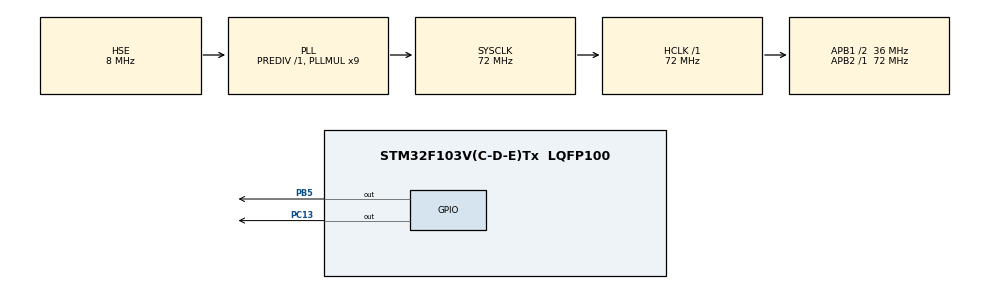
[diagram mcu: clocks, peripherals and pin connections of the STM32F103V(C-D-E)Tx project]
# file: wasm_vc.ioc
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Mcu.Family=STM32F1
Mcu.Name=STM32F103V(C-D-E)Tx
Mcu.Package=LQFP100
NVIC.PriorityGroup=NVIC_PRIORITYGROUP_4
OSC_IN.Mode=HSE-External-Oscillator
OSC_IN.Signal=RCC_OSC_IN
OSC_OUT.Mode=HSE-External-Oscillator
OSC_OUT.Signal=RCC_OSC_OUT
PB5.Signal=GPIO_Output
PC13-TAMPER-RTC.Signal=GPIO_Output
ProjectManager.HeapSize=0x200
ProjectManager.StackSize=0x400
ProjectManager.TargetToolchain=MDK-ARM V5.32
RCC.AHBFreq_Value=72000000
RCC.APB1CLKDivider=RCC_HCLK_DIV2
RCC.APB1Freq_Value=36000000
RCC.APB1TimFreq_Value=72000000
RCC.APB2Freq_Value=72000000
RCC.APB2TimFreq_Value=72000000
RCC.HCLKFreq_Value=72000000
RCC.PLLMUL=RCC_PLL_MUL9
RCC.PLLSourceVirtual=RCC_PLLSOURCE_HSE
RCC.SYSCLKFreq_VALUE=72000000
RCC.SYSCLKSource=RCC_SYSCLKSOURCE_PLLCLK
RCC.USBFreq_Value=72000000
VP_SYS_VS_ND.Mode=No_Debug
board=custom

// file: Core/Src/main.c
/* USER CODE BEGIN Header */
/**
  ******************************************************************************
  * @file           : main.c
  * @brief          : Main program body
  ******************************************************************************
  * @attention
  *
  * Copyright (c) 2023 STMicroelectronics.
  * All rights reserved.
  *
  * This software is licensed under terms that can be found in the LICENSE file
  * in the root directory of this software component.
  * If no LICENSE file comes with this software, it is provided AS-IS.
  *
  ******************************************************************************
  */
/* USER CODE END Header */
#include "main.h"
/* USER CODE BEGIN Includes */
#include"wasm3.h"
#include "fib32.wasm.h"

/* USER CODE END Includes */

void SystemClock_Config(void);
static void MX_GPIO_Init(void);

/* USER CODE BEGIN 0 */
void run_wasm()
{
    M3Result result = m3Err_none;

    uint8_t* wasm = (uint8_t*)fib32_wasm;
    size_t fsize = fib32_wasm_len;

    //puts("Loading WebAssembly...");

    IM3Environment env = m3_NewEnvironment ();
    //if (!env) FATAL("m3_NewEnvironment", "failed");

    IM3Runtime runtime = m3_NewRuntime (env, 1024, NULL);
   // if (!runtime) FATAL("m3_NewRuntime", "failed");

    IM3Module module;
    result = m3_ParseModule (env, &module, wasm, fsize);
   // if (result) FATAL("m3_ParseModule", result);

    result = m3_LoadModule (runtime, module);
    //if (result) FATAL("m3_LoadModule", result);

    IM3Function f;
    result = m3_FindFunction (&f, runtime, "fib");
   // if (result) FATAL("m3_FindFunction", result);

   // puts("Running...");

    result = m3_CallV (f, 24);
  //  if (result) FATAL("m3_Call", result);

    uint32_t value = 0;
    result = m3_GetResultsV (f, &value);
   // if (result) FATAL("m3_GetResults", result);

    char buff[32];
   // itoa(value, buff, 10);

   // puts("Result: ");
  //  puts(buff);
   // puts("\n");
}
/* USER CODE END 0 */

int main(void)
{

  /* MCU Configuration--------------------------------------------------------*/

  /* Reset of all peripherals, Initializes the Flash interface and the Systick. */
  HAL_Init();

  /* Configure the system clock */
  SystemClock_Config();

  /* Initialize all configured peripherals */
  MX_GPIO_Init();
  /* USER CODE BEGIN 2 */
	run_wasm();
  /* USER CODE END 2 */

  /* Infinite loop */
  while (1)
  {

  }
}

void SystemClock_Config(void)
{
  RCC_OscInitTypeDef RCC_OscInitStruct = {0};
  RCC_ClkInitTypeDef RCC_ClkInitStruct = {0};

  /** Initializes the RCC Oscillators according to the specified parameters
  * in the RCC_OscInitTypeDef structure.
  */
  RCC_OscInitStruct.OscillatorType = RCC_OSCILLATORTYPE_HSE;
  RCC_OscInitStruct.HSEState = RCC_HSE_ON;
  RCC_OscInitStruct.HSEPredivValue = RCC_HSE_PREDIV_DIV1;
  RCC_OscInitStruct.HSIState = RCC_HSI_ON;
  RCC_OscInitStruct.PLL.PLLState = RCC_PLL_ON;
  RCC_OscInitStruct.PLL.PLLSource = RCC_PLLSOURCE_HSE;
  RCC_OscInitStruct.PLL.PLLMUL = RCC_PLL_MUL9;
  if (HAL_RCC_OscConfig(&RCC_OscInitStruct) != HAL_OK)
  {
    Error_Handler();
  }

  /** Initializes the CPU, AHB and APB buses clocks
  */
  RCC_ClkInitStruct.ClockType = RCC_CLOCKTYPE_HCLK|RCC_CLOCKTYPE_SYSCLK
                              |RCC_CLOCKTYPE_PCLK1|RCC_CLOCKTYPE_PCLK2;
  RCC_ClkInitStruct.SYSCLKSource = RCC_SYSCLKSOURCE_PLLCLK;
  RCC_ClkInitStruct.AHBCLKDivider = RCC_SYSCLK_DIV1;
  RCC_ClkInitStruct.APB1CLKDivider = RCC_HCLK_DIV2;
  RCC_ClkInitStruct.APB2CLKDivider = RCC_HCLK_DIV1;

  if (HAL_RCC_ClockConfig(&RCC_ClkInitStruct, FLASH_LATENCY_2) != HAL_OK)
  {
    Error_Handler();
  }
}

static void MX_GPIO_Init(void)
{
  GPIO_InitTypeDef GPIO_InitStruct = {0};

  /* GPIO Ports Clock Enable */
  __HAL_RCC_GPIOC_CLK_ENABLE();
  __HAL_RCC_GPIOB_CLK_ENABLE();

  /*Configure GPIO pin Output Level */
  HAL_GPIO_WritePin(GPIOC, GPIO_PIN_13, GPIO_PIN_RESET);

  /*Configure GPIO pin Output Level */
  HAL_GPIO_WritePin(GPIOB, GPIO_PIN_5, GPIO_PIN_RESET);

  /*Configure GPIO pin : PC13 */
  GPIO_InitStruct.Pin = GPIO_PIN_13;
  GPIO_InitStruct.Mode = GPIO_MODE_OUTPUT_PP;
  GPIO_InitStruct.Pull = GPIO_NOPULL;
  GPIO_InitStruct.Speed = GPIO_SPEED_FREQ_LOW;
  HAL_GPIO_Init(GPIOC, &GPIO_InitStruct);

  /*Configure GPIO pin : PB5 */
  GPIO_InitStruct.Pin = GPIO_PIN_5;
  GPIO_InitStruct.Mode = GPIO_MODE_OUTPUT_PP;
  GPIO_InitStruct.Pull = GPIO_NOPULL;
  GPIO_InitStruct.Speed = GPIO_SPEED_FREQ_LOW;
  HAL_GPIO_Init(GPIOB, &GPIO_InitStruct);

}

void Error_Handler(void)
{
  __disable_irq();
  while (1)
  {
  }
}
